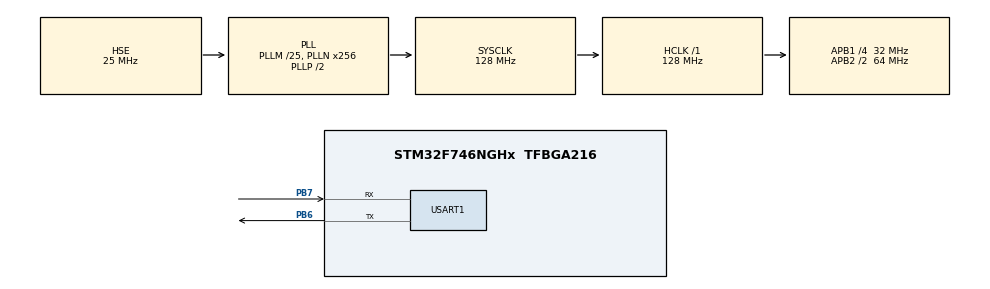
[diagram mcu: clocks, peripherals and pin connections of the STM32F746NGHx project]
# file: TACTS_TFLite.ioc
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CORTEX_M7.ART_ACCELERATOR_ENABLE=1
CORTEX_M7.CPU_DCache=Enabled
CORTEX_M7.CPU_ICache=Enabled
CORTEX_M7.PREFETCH_ENABLE=1
Mcu.Family=STM32F7
Mcu.Name=STM32F746NGHx
Mcu.Package=TFBGA216
NVIC.PriorityGroup=NVIC_PRIORITYGROUP_4
NVIC.TIM7_IRQn=true\:0\:0\:false\:false\:true\:true\:true\:true
NVIC.USART1_IRQn=true\:0\:0\:false\:false\:true\:true\:true\:true
PB6.Mode=Asynchronous
PB6.Signal=USART1_TX
PB7.Mode=Asynchronous
PB7.Signal=USART1_RX
PH0/OSC_IN.Mode=HSE-External-Oscillator
PH0/OSC_IN.Signal=RCC_OSC_IN
PH1/OSC_OUT.Mode=HSE-External-Oscillator
PH1/OSC_OUT.Signal=RCC_OSC_OUT
ProjectManager.HeapSize=0x200
ProjectManager.StackSize=0x800
ProjectManager.TargetToolchain=STM32CubeIDE
RCC.AHBFreq_Value=128000000
RCC.APB1CLKDivider=RCC_HCLK_DIV4
RCC.APB1Freq_Value=32000000
RCC.APB1TimFreq_Value=64000000
RCC.APB2CLKDivider=RCC_HCLK_DIV2
RCC.APB2Freq_Value=64000000
RCC.APB2TimFreq_Value=128000000
RCC.CortexFreq_Value=128000000
RCC.HCLKFreq_Value=128000000
RCC.HSE_VALUE=25000000
RCC.HSI_VALUE=16000000
RCC.LSE_VALUE=32768
RCC.PLLM=25
RCC.PLLN=256
RCC.PLLSourceVirtual=RCC_PLLSOURCE_HSE
RCC.SYSCLKFreq_VALUE=128000000
RCC.SYSCLKSource=RCC_SYSCLKSOURCE_PLLCLK
RCC.USBFreq_Value=128000000
RCC.VCOOutputFreq_Value=256000000
STMicroelectronics.X-CUBE-AI.5.1.2.ActivationBufferSizeList=136
STMicroelectronics.X-CUBE-AI.5.1.2.HeapSize=0x200
STMicroelectronics.X-CUBE-AI.5.1.2.InternalRamActivationBufferMaxSize=AI_SINE_MODEL_DATA_ACTIVATIONS_SIZE
STMicroelectronics.X-CUBE-AI.5.1.2.LatestDirectoryUsed-ade36dd9f2a3e7f240ea64142c58d8794a8e44bac67d2da18166a8c87c8071b4=D\:\\ME program\\2017-PhD\\01_research\\02Study\\34_ballon_like_cover\\DeepLearing\\TACTS\\TensorflowLite
STMicroelectronics.X-CUBE-AI.5.1.2.MaximumNumberOfInputLayer=1
STMicroelectronics.X-CUBE-AI.5.1.2.MaximumNumberOfOutputLayer=1
STMicroelectronics.X-CUBE-AI.5.1.2.MaximumSizeOfInputLayer=AI_SINE_MODEL_IN_1_SIZE_BYTES
STMicroelectronics.X-CUBE-AI.5.1.2.MaximumSizeOfOutputLayer=AI_SINE_MODEL_OUT_1_SIZE_BYTES
STMicroelectronics.X-CUBE-AI.5.1.2.ModelActualCompression-ade36dd9f2a3e7f240ea64142c58d8794a8e44bac67d2da18166a8c87c8071b4=0.0
STMicroelectronics.X-CUBE-AI.5.1.2.ModelCompression-ade36dd9f2a3e7f240ea64142c58d8794a8e44bac67d2da18166a8c87c8071b4=1
STMicroelectronics.X-CUBE-AI.5.1.2.ModelFlashOccupation-ade36dd9f2a3e7f240ea64142c58d8794a8e44bac67d2da18166a8c87c8071b4=2372
STMicroelectronics.X-CUBE-AI.5.1.2.ModelHashList=ade36dd9f2a3e7f240ea64142c58d8794a8e44bac67d2da18166a8c87c8071b4
STMicroelectronics.X-CUBE-AI.5.1.2.ModelKind-ade36dd9f2a3e7f240ea64142c58d8794a8e44bac67d2da18166a8c87c8071b4=TFLITE
STMicroelectronics.X-CUBE-AI.5.1.2.ModelMacc-ade36dd9f2a3e7f240ea64142c58d8794a8e44bac67d2da18166a8c87c8071b4=592
STMicroelectronics.X-CUBE-AI.5.1.2.ModelName-ade36dd9f2a3e7f240ea64142c58d8794a8e44bac67d2da18166a8c87c8071b4=sine_model
STMicroelectronics.X-CUBE-AI.5.1.2.ModelNameList=sine_model
STMicroelectronics.X-CUBE-AI.5.1.2.ModelRamOccupation-ade36dd9f2a3e7f240ea64142c58d8794a8e44bac67d2da18166a8c87c8071b4=136
STMicroelectronics.X-CUBE-AI.5.1.2.ModelStructureFile-ade36dd9f2a3e7f240ea64142c58d8794a8e44bac67d2da18166a8c87c8071b4=D\:\\ME program\\2017-PhD\\01_research\\02Study\\34_ballon_like_cover\\DeepLearing\\TACTS\\TensorflowLite\\sine_model.tflite
STMicroelectronics.X-CUBE-AI.5.1.2.ModelType-ade36dd9f2a3e7f240ea64142c58d8794a8e44bac67d2da18166a8c87c8071b4=Saved model
STMicroelectronics.X-CUBE-AI.5.1.2.StackSize=0x800
STMicroelectronics.X-CUBE-AI.5.1.2.WorkingBufferStartAddrList=0xFFFFFFFF
STMicroelectronics.X-CUBE-AI.5.1.2.XAaCUBEAaAICcArtificialOoIntelligenceJjCore=true
TIM7.Prescaler=128-1
USART1.VirtualMode-Asynchronous=VM_ASYNC
VP_CRC_VS_CRC.Mode=CRC_Activate
VP_STMicroelectronics.X-CUBE-AI_VS_ArtificialOoIntelligenceJjXAaCUBEAaAI_5.1.2.Mode=ArtificialOoIntelligenceJjXAaCUBEAaAI
VP_TIM7_VS_ClockSourceINT.Mode=Enable_Timer
board=custom

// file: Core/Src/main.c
/* USER CODE BEGIN Header */
/**
  ******************************************************************************
  * @file           : main.c
  * @brief          : Main program body
  ******************************************************************************
  * @attention
  *
  * Copyright (c) 2023 STMicroelectronics.
  * All rights reserved.
  *
  * This software is licensed under terms that can be found in the LICENSE file
  * in the root directory of this software component.
  * If no LICENSE file comes with this software, it is provided AS-IS.
  *
  ******************************************************************************
  */
/* USER CODE END Header */
#include "main.h"

/* USER CODE BEGIN Includes */
#include <stdio.h>

#include "ai_datatypes_defines.h"
#include "ai_platform.h"
#include "sine_model.h"
#include "sine_model_data.h"
/* USER CODE END Includes */

CRC_HandleTypeDef hcrc;

TIM_HandleTypeDef htim7;

UART_HandleTypeDef huart1;

void SystemClock_Config(void);
static void MX_GPIO_Init(void);
static void MX_CRC_Init(void);
static void MX_TIM7_Init(void);
static void MX_USART1_UART_Init(void);

int main(void)
{
  /* USER CODE BEGIN 1 */
	char buf[50];
	int buf_len = 0;
	ai_error ai_err;
	ai_i32 nbatch;
	uint32_t timestamp;
	float y_val;

	// Chunk of memory used to hold intermediate values for neural network
	AI_ALIGNED(4) ai_u8 activations[AI_SINE_MODEL_DATA_ACTIVATIONS_SIZE];

	// Buffers used to store input and output tensors
	AI_ALIGNED(4) ai_i8 in_data[AI_SINE_MODEL_IN_1_SIZE_BYTES];
	AI_ALIGNED(4) ai_i8 out_data[AI_SINE_MODEL_OUT_1_SIZE_BYTES];

	// Pointer to our model
	ai_handle sine_model = AI_HANDLE_NULL;

	// Initialize wrapper structs that hold pointers to data and info about the
	// data (tensor height, width, channels)
	ai_buffer ai_input[AI_SINE_MODEL_IN_NUM] = AI_SINE_MODEL_IN;
	ai_buffer ai_output[AI_SINE_MODEL_OUT_NUM] = AI_SINE_MODEL_OUT;

	// Set working memory and get weights/biases from model
	ai_network_params ai_params = {
	AI_SINE_MODEL_DATA_WEIGHTS(ai_sine_model_data_weights_get()),
	AI_SINE_MODEL_DATA_ACTIVATIONS(activations)
	};

	// Set pointers wrapper structs to our data buffers
	ai_input[0].n_batches = 1;
	ai_input[0].data = AI_HANDLE_PTR(in_data);
	ai_output[0].n_batches = 1;
	ai_output[0].data = AI_HANDLE_PTR(out_data);
  /* USER CODE END 1 */

  /* Enable I-Cache---------------------------------------------------------*/
  SCB_EnableICache();

  /* Enable D-Cache---------------------------------------------------------*/
  SCB_EnableDCache();

  /* MCU Configuration--------------------------------------------------------*/

  /* Reset of all peripherals, Initializes the Flash interface and the Systick. */
  HAL_Init();

  /* Configure the system clock */
  SystemClock_Config();

  /* Initialize all configured peripherals */
  MX_GPIO_Init();
  MX_CRC_Init();
  MX_TIM7_Init();
  MX_USART1_UART_Init();
  /* USER CODE BEGIN 2 */

  HAL_TIM_Base_Start(&htim6);

   // Greetings!
   buf_len = sprintf(buf, "\r\n\r\nSTM32 X-Cube-AI test\r\n");
   HAL_UART_Transmit(&huart1, (uint8_t *)buf, buf_len, 100);

   // Create instance of neural network
   ai_err = ai_sine_model_create(&sine_model, AI_SINE_MODEL_DATA_CONFIG);
   if (ai_err.type != AI_ERROR_NONE)
   {
     buf_len = sprintf(buf, "Error: could not create NN instance\r\n");
     HAL_UART_Transmit(&huart1, (uint8_t *)buf, buf_len, 100);
     while(1);
   }

   // Initialize neural network
   if (!ai_sine_model_init(sine_model, &ai_params))
   {
     buf_len = sprintf(buf, "Error: could not initialize NN\r\n");
     HAL_UART_Transmit(&huart1, (uint8_t *)buf, buf_len, 100);
     while(1);
   }

  /* USER CODE END 2 */

  /* Infinite loop */
  while (1)
  {

  }
}

void SystemClock_Config(void)
{
  RCC_OscInitTypeDef RCC_OscInitStruct = {0};
  RCC_ClkInitTypeDef RCC_ClkInitStruct = {0};

  /** Configure the main internal regulator output voltage
  */
  __HAL_RCC_PWR_CLK_ENABLE();
  __HAL_PWR_VOLTAGESCALING_CONFIG(PWR_REGULATOR_VOLTAGE_SCALE3);

  /** Initializes the RCC Oscillators according to the specified parameters
  * in the RCC_OscInitTypeDef structure.
  */
  RCC_OscInitStruct.OscillatorType = RCC_OSCILLATORTYPE_HSE;
  RCC_OscInitStruct.HSEState = RCC_HSE_ON;
  RCC_OscInitStruct.PLL.PLLState = RCC_PLL_ON;
  RCC_OscInitStruct.PLL.PLLSource = RCC_PLLSOURCE_HSE;
  RCC_OscInitStruct.PLL.PLLM = 25;
  RCC_OscInitStruct.PLL.PLLN = 256;
  RCC_OscInitStruct.PLL.PLLP = RCC_PLLP_DIV2;
  RCC_OscInitStruct.PLL.PLLQ = 2;
  if (HAL_RCC_OscConfig(&RCC_OscInitStruct) != HAL_OK)
  {
    Error_Handler();
  }

  /** Initializes the CPU, AHB and APB buses clocks
  */
  RCC_ClkInitStruct.ClockType = RCC_CLOCKTYPE_HCLK|RCC_CLOCKTYPE_SYSCLK
                              |RCC_CLOCKTYPE_PCLK1|RCC_CLOCKTYPE_PCLK2;
  RCC_ClkInitStruct.SYSCLKSource = RCC_SYSCLKSOURCE_PLLCLK;
  RCC_ClkInitStruct.AHBCLKDivider = RCC_SYSCLK_DIV1;
  RCC_ClkInitStruct.APB1CLKDivider = RCC_HCLK_DIV4;
  RCC_ClkInitStruct.APB2CLKDivider = RCC_HCLK_DIV2;

  if (HAL_RCC_ClockConfig(&RCC_ClkInitStruct, FLASH_LATENCY_4) != HAL_OK)
  {
    Error_Handler();
  }
}

static void MX_CRC_Init(void)
{

  hcrc.Instance = CRC;
  hcrc.Init.DefaultPolynomialUse = DEFAULT_POLYNOMIAL_ENABLE;
  hcrc.Init.DefaultInitValueUse = DEFAULT_INIT_VALUE_ENABLE;
  hcrc.Init.InputDataInversionMode = CRC_INPUTDATA_INVERSION_NONE;
  hcrc.Init.OutputDataInversionMode = CRC_OUTPUTDATA_INVERSION_DISABLE;
  hcrc.InputDataFormat = CRC_INPUTDATA_FORMAT_BYTES;
  if (HAL_CRC_Init(&hcrc) != HAL_OK)
  {
    Error_Handler();
  }

}

static void MX_TIM7_Init(void)
{

  TIM_MasterConfigTypeDef sMasterConfig = {0};

  htim7.Instance = TIM7;
  htim7.Init.Prescaler = 128-1;
  htim7.Init.CounterMode = TIM_COUNTERMODE_UP;
  htim7.Init.Period = 65535;
  htim7.Init.AutoReloadPreload = TIM_AUTORELOAD_PRELOAD_DISABLE;
  if (HAL_TIM_Base_Init(&htim7) != HAL_OK)
  {
    Error_Handler();
  }
  sMasterConfig.MasterOutputTrigger = TIM_TRGO_RESET;
  sMasterConfig.MasterSlaveMode = TIM_MASTERSLAVEMODE_DISABLE;
  if (HAL_TIMEx_MasterConfigSynchronization(&htim7, &sMasterConfig) != HAL_OK)
  {
    Error_Handler();
  }

}

static void MX_USART1_UART_Init(void)
{

  huart1.Instance = USART1;
  huart1.Init.BaudRate = 115200;
  huart1.Init.WordLength = UART_WORDLENGTH_8B;
  huart1.Init.StopBits = UART_STOPBITS_1;
  huart1.Init.Parity = UART_PARITY_NONE;
  huart1.Init.Mode = UART_MODE_TX_RX;
  huart1.Init.HwFlowCtl = UART_HWCONTROL_NONE;
  huart1.Init.OverSampling = UART_OVERSAMPLING_16;
  huart1.Init.OneBitSampling = UART_ONE_BIT_SAMPLE_DISABLE;
  huart1.AdvancedInit.AdvFeatureInit = UART_ADVFEATURE_NO_INIT;
  if (HAL_UART_Init(&huart1) != HAL_OK)
  {
    Error_Handler();
  }

}

static void MX_GPIO_Init(void)
{

  /* GPIO Ports Clock Enable */
  __HAL_RCC_GPIOB_CLK_ENABLE();
  __HAL_RCC_GPIOH_CLK_ENABLE();

}

void Error_Handler(void)
{
  __disable_irq();
  while (1)
  {
  }
}
